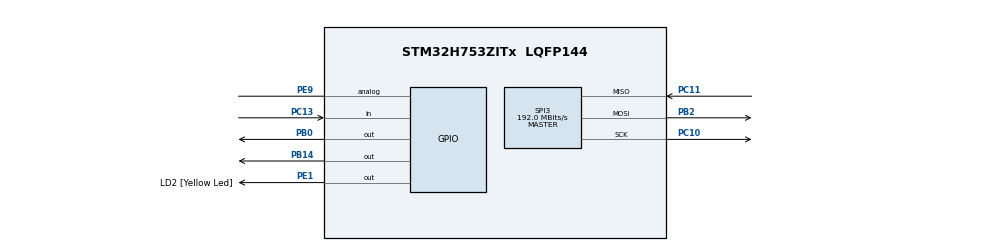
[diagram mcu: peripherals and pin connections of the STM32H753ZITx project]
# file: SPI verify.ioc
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CORTEX_M7.CPU_DCache=Disabled
CORTEX_M7.CPU_ICache=Disabled
CORTEX_M7.MPU_Control=__NULL
CORTEX_M7.default_mode_Activation=1
Mcu.Family=STM32H7
Mcu.Name=STM32H753ZITx
Mcu.Package=LQFP144
NUCLEO-H753ZI.BUTTON=1
NUCLEO-H753ZI.LD1=true
NUCLEO-H753ZI.LD2=true
NUCLEO-H753ZI.LD3=true
NUCLEO-H753ZI.VCP=true
NVIC.EXTI15_10_IRQn=true\:0\:0\:false\:false\:true\:false\:true\:true
NVIC.PriorityGroup=NVIC_PRIORITYGROUP_4
PB0.Signal=GPIO_Output
PB14.Signal=GPIO_Output
PB2.Mode=Full_Duplex_Master
PB2.Signal=SPI3_MOSI
PC10.Mode=Full_Duplex_Master
PC10.Signal=SPI3_SCK
PC11.Mode=Full_Duplex_Master
PC11.Signal=SPI3_MISO
PC13.Signal=GPIO_Input
PC14-OSC32_IN\ (OSC32_IN).Signal=RCC_OSC32_IN
PC15-OSC32_OUT\ (OSC32_OUT).Signal=RCC_OSC32_OUT
PD8.Signal=USART3_TX
PD9.Signal=USART3_RX
PE1.GPIO_Label=LD2 [Yellow Led]
PE1.Signal=GPIO_Output
PE9.Signal=GPIO_Analog
PH0-OSC_IN\ (PH0).Signal=RCC_OSC_IN
PH1-OSC_OUT\ (PH1).Signal=RCC_OSC_OUT
ProjectManager.HeapSize=0x200
ProjectManager.StackSize=0x400
ProjectManager.TargetToolchain=STM32CubeIDE
RCC.ADCFreq_Value=129000000
RCC.APB1Freq_Value=64000000
RCC.APB2Freq_Value=64000000
RCC.APB3Freq_Value=64000000
RCC.APB4Freq_Value=64000000
RCC.CortexFreq_Value=64000000
RCC.DIVM1=1
RCC.DIVN1=24
RCC.DIVQ1=4
RCC.HCLKFreq_Value=64000000
RCC.HSE_VALUE=8000000
RCC.PLLFRACN=0
RCC.PWR_Regulator_Voltage_Scale=PWR_REGULATOR_VOLTAGE_SCALE2
RCC.SYSCLKFreq_VALUE=64000000
RCC.USBFreq_Value=384000000
SPI3.BaudRatePrescaler=SPI_BAUDRATEPRESCALER_2
SPI3.CalculateBaudRate=192.0 MBits/s
SPI3.Direction=SPI_DIRECTION_2LINES
SPI3.Mode=SPI_MODE_MASTER
SPI3.VirtualType=VM_MASTER
VP_MEMORYMAP_VS_MEMORYMAP.Mode=CurAppReg
VP_NUCLEO-H753ZI_VS_BSP_COMMON.Mode=COMMON
board=NUCLEO-H753ZI

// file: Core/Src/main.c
/* USER CODE BEGIN Header */
/**
  ******************************************************************************
  * @file           : main.c
  * @brief          : Main program body
  ******************************************************************************
  * @attention
  *
  * Copyright (c) 2025 STMicroelectronics.
  * All rights reserved.
  *
  * This software is licensed under terms that can be found in the LICENSE file
  * in the root directory of this software component.
  * If no LICENSE file comes with this software, it is provided AS-IS.
  *
  ******************************************************************************
  */
/* USER CODE END Header */
#include "main.h"

/* USER CODE BEGIN PTD */
void print_uart(const char *format, ...);
/* USER CODE END PTD */

COM_InitTypeDef BspCOMInit;

SPI_HandleTypeDef hspi3;

void SystemClock_Config(void);
static void MX_GPIO_Init(void);
static void MX_SPI3_Init(void);

int main(void)
{

  /* MCU Configuration--------------------------------------------------------*/

  /* Reset of all peripherals, Initializes the Flash interface and the Systick. */
  HAL_Init();

  /* Configure the system clock */
  SystemClock_Config();

  /* Initialize all configured peripherals */
  MX_GPIO_Init();
  MX_SPI3_Init();

  /* Initialize leds */
  BSP_LED_Init(LED_GREEN);
  BSP_LED_Init(LED_BLUE);
  BSP_LED_Init(LED_RED);

  /* Initialize USER push-button, will be used to trigger an interrupt each time it's pressed.*/
  BSP_PB_Init(BUTTON_USER, BUTTON_MODE_EXTI);

  /* Initialize COM1 port (115200, 8 bits (7-bit data + 1 stop bit), no parity */
  BspCOMInit.BaudRate   = 115200;
  BspCOMInit.WordLength = COM_WORDLENGTH_8B;
  BspCOMInit.StopBits   = COM_STOPBITS_1;
  BspCOMInit.Parity     = COM_PARITY_NONE;
  BspCOMInit.HwFlowCtl  = COM_HWCONTROL_NONE;
  if (BSP_COM_Init(COM1, &BspCOMInit) != BSP_ERROR_NONE)
  {
    Error_Handler();
  }

  /* Infinite loop */
  /* USER CODE BEGIN WHILE */
  while (1)
  {
      HAL_GPIO_WritePin(GPIOE, GPIO_PIN_9, GPIO_PIN_RESET); // Pull CS LOW
      HAL_SPI_Transmit(&hspi3, spi_tx_data, strlen((char*)spi_tx_data), HAL_MAX_DELAY);
      HAL_GPIO_WritePin(GPIOE, GPIO_PIN_9, GPIO_PIN_SET);   // Pull CS HIGH

      HAL_Delay(1000); // Wait 1 second before next send
  }

void SystemClock_Config(void)
{
  RCC_OscInitTypeDef RCC_OscInitStruct = {0};
  RCC_ClkInitTypeDef RCC_ClkInitStruct = {0};

  /** Supply configuration update enable
  */
  HAL_PWREx_ConfigSupply(PWR_LDO_SUPPLY);

  /** Configure the main internal regulator output voltage
  */
  __HAL_PWR_VOLTAGESCALING_CONFIG(PWR_REGULATOR_VOLTAGE_SCALE2);

  while(!__HAL_PWR_GET_FLAG(PWR_FLAG_VOSRDY)) {}

  /** Initializes the RCC Oscillators according to the specified parameters
  * in the RCC_OscInitTypeDef structure.
  */
  RCC_OscInitStruct.OscillatorType = RCC_OSCILLATORTYPE_HSI;
  RCC_OscInitStruct.HSIState = RCC_HSI_DIV1;
  RCC_OscInitStruct.HSICalibrationValue = RCC_HSICALIBRATION_DEFAULT;
  RCC_OscInitStruct.PLL.PLLState = RCC_PLL_ON;
  RCC_OscInitStruct.PLL.PLLSource = RCC_PLLSOURCE_HSI;
  RCC_OscInitStruct.PLL.PLLM = 1;
  RCC_OscInitStruct.PLL.PLLN = 24;
  RCC_OscInitStruct.PLL.PLLP = 2;
  RCC_OscInitStruct.PLL.PLLQ = 4;
  RCC_OscInitStruct.PLL.PLLR = 2;
  RCC_OscInitStruct.PLL.PLLRGE = RCC_PLL1VCIRANGE_3;
  RCC_OscInitStruct.PLL.PLLVCOSEL = RCC_PLL1VCOWIDE;
  RCC_OscInitStruct.PLL.PLLFRACN = 0;
  if (HAL_RCC_OscConfig(&RCC_OscInitStruct) != HAL_OK)
  {
    Error_Handler();
  }

  /** Initializes the CPU, AHB and APB buses clocks
  */
  RCC_ClkInitStruct.ClockType = RCC_CLOCKTYPE_HCLK|RCC_CLOCKTYPE_SYSCLK
                              |RCC_CLOCKTYPE_PCLK1|RCC_CLOCKTYPE_PCLK2
                              |RCC_CLOCKTYPE_D3PCLK1|RCC_CLOCKTYPE_D1PCLK1;
  RCC_ClkInitStruct.SYSCLKSource = RCC_SYSCLKSOURCE_HSI;
  RCC_ClkInitStruct.SYSCLKDivider = RCC_SYSCLK_DIV1;
  RCC_ClkInitStruct.AHBCLKDivider = RCC_HCLK_DIV1;
  RCC_ClkInitStruct.APB3CLKDivider = RCC_APB3_DIV1;
  RCC_ClkInitStruct.APB1CLKDivider = RCC_APB1_DIV1;
  RCC_ClkInitStruct.APB2CLKDivider = RCC_APB2_DIV1;
  RCC_ClkInitStruct.APB4CLKDivider = RCC_APB4_DIV1;

  if (HAL_RCC_ClockConfig(&RCC_ClkInitStruct, FLASH_LATENCY_1) != HAL_OK)
  {
    Error_Handler();
  }
}

static void MX_SPI3_Init(void)
{

  /* SPI3 parameter configuration*/
  hspi3.Instance = SPI3;
  hspi3.Init.Mode = SPI_MODE_MASTER;
  hspi3.Init.Direction = SPI_DIRECTION_2LINES;
  hspi3.Init.DataSize = SPI_DATASIZE_8BIT;
  hspi3.Init.CLKPolarity = SPI_POLARITY_LOW;
  hspi3.Init.CLKPhase = SPI_PHASE_1EDGE;
  hspi3.Init.NSS = SPI_NSS_SOFT;
  hspi3.Init.BaudRatePrescaler = SPI_BAUDRATEPRESCALER_2;
  hspi3.Init.FirstBit = SPI_FIRSTBIT_MSB;
  hspi3.Init.TIMode = SPI_TIMODE_DISABLE;
  hspi3.Init.CRCCalculation = SPI_CRCCALCULATION_DISABLE;
  hspi3.Init.CRCPolynomial = 0x0;
  hspi3.Init.NSSPMode = SPI_NSS_PULSE_ENABLE;
  hspi3.Init.NSSPolarity = SPI_NSS_POLARITY_LOW;
  hspi3.Init.FifoThreshold = SPI_FIFO_THRESHOLD_01DATA;
  hspi3.Init.TxCRCInitializationPattern = SPI_CRC_INITIALIZATION_ALL_ZERO_PATTERN;
  hspi3.Init.RxCRCInitializationPattern = SPI_CRC_INITIALIZATION_ALL_ZERO_PATTERN;
  hspi3.Init.MasterSSIdleness = SPI_MASTER_SS_IDLENESS_00CYCLE;
  hspi3.Init.MasterInterDataIdleness = SPI_MASTER_INTERDATA_IDLENESS_00CYCLE;
  hspi3.Init.MasterReceiverAutoSusp = SPI_MASTER_RX_AUTOSUSP_DISABLE;
  hspi3.Init.MasterKeepIOState = SPI_MASTER_KEEP_IO_STATE_DISABLE;
  hspi3.Init.IOSwap = SPI_IO_SWAP_DISABLE;
  if (HAL_SPI_Init(&hspi3) != HAL_OK)
  {
    Error_Handler();
  }

}

static void MX_GPIO_Init(void)
{
  GPIO_InitTypeDef GPIO_InitStruct = {0};

  /* GPIO Ports Clock Enable */
  __HAL_RCC_GPIOC_CLK_ENABLE();
  __HAL_RCC_GPIOH_CLK_ENABLE();
  __HAL_RCC_GPIOB_CLK_ENABLE();
  __HAL_RCC_GPIOE_CLK_ENABLE();

  /*Configure GPIO pin Output Level */
  HAL_GPIO_WritePin(LD2_GPIO_Port, LD2_Pin, GPIO_PIN_RESET);

  /*Configure GPIO pin : PE9 */
  GPIO_InitStruct.Pin = GPIO_PIN_9;
  GPIO_InitStruct.Mode = GPIO_MODE_ANALOG;
  GPIO_InitStruct.Pull = GPIO_NOPULL;
  HAL_GPIO_Init(GPIOE, &GPIO_InitStruct);

  /*Configure GPIO pin : LD2_Pin */
  GPIO_InitStruct.Pin = LD2_Pin;
  GPIO_InitStruct.Mode = GPIO_MODE_OUTPUT_PP;
  GPIO_InitStruct.Pull = GPIO_NOPULL;
  GPIO_InitStruct.Speed = GPIO_SPEED_FREQ_LOW;
  HAL_GPIO_Init(LD2_GPIO_Port, &GPIO_InitStruct);

}

/* USER CODE BEGIN 4 */
void print_uart(const char *format, ...)
{
    char uart_buffer[128];  // adjust size if needed
    va_list args;
    va_start(args, format);
    vsnprintf(uart_buffer, sizeof(uart_buffer), format, args);
    va_end(args);

    HAL_UART_Transmit(&huart3, (uint8_t *)uart_buffer, strlen(uart_buffer), HAL_MAX_DELAY);
}
/* USER CODE END 4 */

void Error_Handler(void)
{
  __disable_irq();
  while (1)
  {
  }
}
